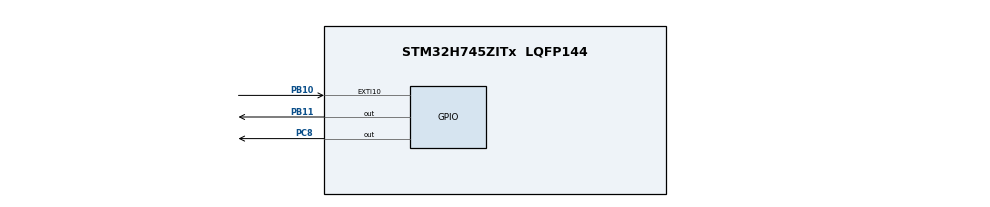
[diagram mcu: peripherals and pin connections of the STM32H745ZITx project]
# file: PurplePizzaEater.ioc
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CortexM4.IPs=BDMA,CORTEX_M4\:I,DEBUG,DMA,FATFS_M4\:I,FREERTOS_M4\:I,IWDG2\:I,MDMA,NVIC2\:I,OPENAMP_M4\:I,PDM2PCM_M4\:I,PWR,RCC,RESMGR_UTILITY,SYS_M4\:I,USB_DEVICE_M4\:I,USB_HOST_M4\:I,VREFBUF,WWDG2\:I
CortexM4.Pins=PC8
CortexM7.IPs=BDMA\:I,CORTEX_M7\:I,DEBUG\:I,DMA\:I,FATFS_M7\:I,FREERTOS_M7\:I,IWDG1\:I,MDMA\:I,NVIC1\:I,OPENAMP_M7\:I,PDM2PCM_M7\:I,PWR\:I,RCC\:I,RESMGR_UTILITY\:I,SYS\:I,USB_DEVICE_M7\:I,USB_HOST_M7\:I,VREFBUF\:I,WWDG1\:I
CortexM7.Pins=PB10,PB11
Mcu.Family=STM32H7
Mcu.Name=STM32H745ZITx
Mcu.Package=LQFP144
NVIC1.EXTI15_10_IRQn=true\:0\:0\:false\:false\:true\:true\:true
NVIC1.PriorityGroup=NVIC_PRIORITYGROUP_4
NVIC2.PriorityGroup=NVIC_PRIORITYGROUP_4
PB10.GPIO_ModeDefaultEXTI=GPIO_MODE_IT_FALLING
PB10.GPIO_PuPd=GPIO_NOPULL
PB10.PinAttribute=CortexM7
PB10.Signal=GPXTI10
PB11.PinAttribute=CortexM7
PB11.Signal=GPIO_Output
PC8.PinAttribute=CortexM4
PC8.Signal=GPIO_Output
ProjectManager.HeapSize=M4-0x200,M7-0x200
ProjectManager.StackSize=M4-0x400,M7-0x400
ProjectManager.TargetToolchain=STM32CubeIDE
RCC.ADCFreq_Value=129000000
RCC.APB1Freq_Value=64000000
RCC.APB2Freq_Value=64000000
RCC.APB3Freq_Value=64000000
RCC.APB4Freq_Value=64000000
RCC.CortexFreq_Value=64000000
RCC.HCLKFreq_Value=64000000
RCC.SYSCLKFreq_VALUE=64000000
RCC.USBFreq_Value=129000000
SYS.userName=SYS_M7
VP_SYS_M4_VS_Systick.Mode=SysTick
board=custom

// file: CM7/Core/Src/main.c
/* USER CODE BEGIN Header */
/**
 ******************************************************************************
 * @file           : main.c
 * @brief          : Main program body
 ******************************************************************************
 * @attention
 *
 * <h2><center>&copy; Copyright (c) 2021 STMicroelectronics.
 * All rights reserved.</center></h2>
 *
 * This software component is licensed by ST under BSD 3-Clause license,
 * the "License"; You may not use this file except in compliance with the
 * License. You may obtain a copy of the License at:
 *                        opensource.org/licenses/BSD-3-Clause
 *
 ******************************************************************************
 */
/* USER CODE END Header */
#include "main.h"

/* USER CODE BEGIN PD */

#ifndef HSEM_ID_0
#define HSEM_ID_0 (0U) /* HW semaphore 0*/
#endif
/* USER CODE END PD */

void SystemClock_Config(void);
static void MX_GPIO_Init(void);

int main(void)
{
/* USER CODE BEGIN Boot_Mode_Sequence_0 */
	int32_t timeout;
/* USER CODE END Boot_Mode_Sequence_0 */

/* USER CODE BEGIN Boot_Mode_Sequence_1 */
	/* Wait until CPU2 boots and enters in stop mode or timeout*/
	timeout = 0xFFFF;
	while ((__HAL_RCC_GET_FLAG(RCC_FLAG_D2CKRDY) != RESET) && (timeout-- > 0))
		;
	if (timeout < 0) {
		Error_Handler();
	}
/* USER CODE END Boot_Mode_Sequence_1 */
  /* MCU Configuration--------------------------------------------------------*/

  /* Reset of all peripherals, Initializes the Flash interface and the Systick. */
  HAL_Init();

  /* Configure the system clock */
  SystemClock_Config();
/* USER CODE BEGIN Boot_Mode_Sequence_2 */
	/* When system initialization is finished, Cortex-M7 will release Cortex-M4 by means of
	 HSEM notification */
	/*HW semaphore Clock enable*/
	__HAL_RCC_HSEM_CLK_ENABLE();
	/*Take HSEM */
	HAL_HSEM_FastTake(HSEM_ID_0);
	/*Release HSEM in order to notify the CPU2(CM4)*/
	HAL_HSEM_Release(HSEM_ID_0, 0);
	/* wait until CPU2 wakes up from stop mode */
	timeout = 0xFFFF;
	while ((__HAL_RCC_GET_FLAG(RCC_FLAG_D2CKRDY) == RESET) && (timeout-- > 0));
	if (timeout < 0) {
		Error_Handler();
	}
/* USER CODE END Boot_Mode_Sequence_2 */

  /* Initialize all configured peripherals */
  MX_GPIO_Init();

  /* Infinite loop */
  /* USER CODE BEGIN WHILE */
	while (1) {
		//HAL_GPIO_TogglePin(GPIOB, GPIO_PIN_11);
		//HAL_GPIO_ReadPin(GPIOB, GPIO_PIN_10);
		//HAL_Delay(500);
    /* USER CODE END WHILE */

	}
}

void SystemClock_Config(void)
{
  RCC_OscInitTypeDef RCC_OscInitStruct = {0};
  RCC_ClkInitTypeDef RCC_ClkInitStruct = {0};

  /** Supply configuration update enable
  */
  HAL_PWREx_ConfigSupply(PWR_DIRECT_SMPS_SUPPLY);
  /** Configure the main internal regulator output voltage
  */
  __HAL_PWR_VOLTAGESCALING_CONFIG(PWR_REGULATOR_VOLTAGE_SCALE3);

  while(!__HAL_PWR_GET_FLAG(PWR_FLAG_VOSRDY)) {}
  /** Initializes the RCC Oscillators according to the specified parameters
  * in the RCC_OscInitTypeDef structure.
  */
  RCC_OscInitStruct.OscillatorType = RCC_OSCILLATORTYPE_HSI;
  RCC_OscInitStruct.HSIState = RCC_HSI_DIV1;
  RCC_OscInitStruct.HSICalibrationValue = RCC_HSICALIBRATION_DEFAULT;
  RCC_OscInitStruct.PLL.PLLState = RCC_PLL_NONE;
  if (HAL_RCC_OscConfig(&RCC_OscInitStruct) != HAL_OK)
  {
    Error_Handler();
  }
  /** Initializes the CPU, AHB and APB buses clocks
  */
  RCC_ClkInitStruct.ClockType = RCC_CLOCKTYPE_HCLK|RCC_CLOCKTYPE_SYSCLK
                              |RCC_CLOCKTYPE_PCLK1|RCC_CLOCKTYPE_PCLK2
                              |RCC_CLOCKTYPE_D3PCLK1|RCC_CLOCKTYPE_D1PCLK1;
  RCC_ClkInitStruct.SYSCLKSource = RCC_SYSCLKSOURCE_HSI;
  RCC_ClkInitStruct.SYSCLKDivider = RCC_SYSCLK_DIV1;
  RCC_ClkInitStruct.AHBCLKDivider = RCC_HCLK_DIV1;
  RCC_ClkInitStruct.APB3CLKDivider = RCC_APB3_DIV1;
  RCC_ClkInitStruct.APB1CLKDivider = RCC_APB1_DIV1;
  RCC_ClkInitStruct.APB2CLKDivider = RCC_APB2_DIV1;
  RCC_ClkInitStruct.APB4CLKDivider = RCC_APB4_DIV1;

  if (HAL_RCC_ClockConfig(&RCC_ClkInitStruct, FLASH_LATENCY_1) != HAL_OK)
  {
    Error_Handler();
  }
}

static void MX_GPIO_Init(void)
{
  GPIO_InitTypeDef GPIO_InitStruct = {0};

  /* GPIO Ports Clock Enable */
  __HAL_RCC_GPIOB_CLK_ENABLE();

  /*Configure GPIO pin Output Level */
  HAL_GPIO_WritePin(GPIOB, GPIO_PIN_11, GPIO_PIN_RESET);

  /*Configure GPIO pin : PB10 */
  GPIO_InitStruct.Pin = GPIO_PIN_10;
  GPIO_InitStruct.Mode = GPIO_MODE_IT_FALLING;
  GPIO_InitStruct.Pull = GPIO_NOPULL;
  HAL_GPIO_Init(GPIOB, &GPIO_InitStruct);

  /*Configure GPIO pin : PB11 */
  GPIO_InitStruct.Pin = GPIO_PIN_11;
  GPIO_InitStruct.Mode = GPIO_MODE_OUTPUT_PP;
  GPIO_InitStruct.Pull = GPIO_NOPULL;
  GPIO_InitStruct.Speed = GPIO_SPEED_FREQ_LOW;
  HAL_GPIO_Init(GPIOB, &GPIO_InitStruct);

  /* EXTI interrupt init*/
  HAL_NVIC_SetPriority(EXTI15_10_IRQn, 0, 0);
  HAL_NVIC_EnableIRQ(EXTI15_10_IRQn);

}

/* USER CODE BEGIN 4 */

// EXTI Line9 External Interrupt ISR Handler CallBackFun
void HAL_GPIO_EXTI_Callback(uint16_t GPIO_Pin) {

	// If The INT Source Is EXTI Line9 (B10 Pin)
	if (GPIO_Pin == GPIO_PIN_10) {
		// Toggle The Output (LED) Pin
		HAL_GPIO_TogglePin(GPIOB, GPIO_PIN_11);
	}
}

/* USER CODE END 4 */

void Error_Handler(void)
{
	__disable_irq();
	while (1) {
	}
}

/************************ (C) COPYRIGHT STMicroelectronics *****END OF FILE****/
